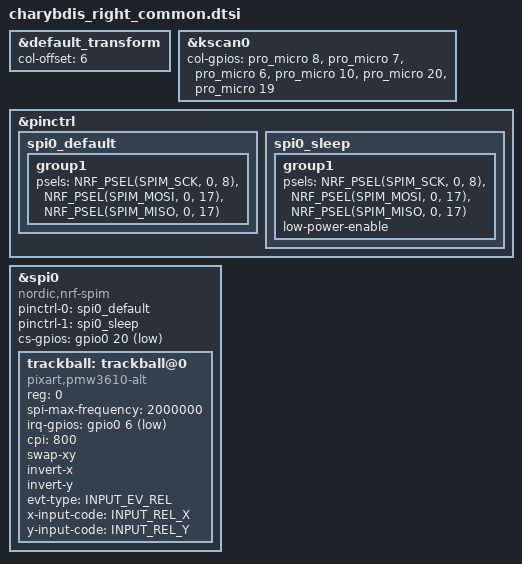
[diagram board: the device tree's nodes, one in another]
/*
 * Copyright (c) 2024 The ZMK Contributors
 * SPDX-License-Identifier: MIT
 *
 * Common hardware configuration for Charybdis right keyboard variants
 * Shared between charybdis_right_standalone and dongle_charybdis_right
 */

#include "charybdis.dtsi"
#include <zephyr/dt-bindings/input/input-event-codes.h>

&default_transform {
	col-offset = <6>;
};

&kscan0 {
	col-gpios
		= <&pro_micro 8 (GPIO_ACTIVE_HIGH | GPIO_PULL_DOWN)>
		, <&pro_micro 7 (GPIO_ACTIVE_HIGH | GPIO_PULL_DOWN)>
		, <&pro_micro 6 (GPIO_ACTIVE_HIGH | GPIO_PULL_DOWN)>
		, <&pro_micro 10 (GPIO_ACTIVE_HIGH | GPIO_PULL_DOWN)>
		, <&pro_micro 20 (GPIO_ACTIVE_HIGH | GPIO_PULL_DOWN)>
		, <&pro_micro 19 (GPIO_ACTIVE_HIGH | GPIO_PULL_DOWN)>
  ;
};

&pinctrl {
    spi0_default: spi0_default {
        group1 {
            psels = <NRF_PSEL(SPIM_SCK, 0, 8)>,
                <NRF_PSEL(SPIM_MOSI, 0, 17)>,
                <NRF_PSEL(SPIM_MISO, 0, 17)>;
        };
    };

    spi0_sleep: spi0_sleep {
        group1 {
            psels = <NRF_PSEL(SPIM_SCK, 0, 8)>,
                <NRF_PSEL(SPIM_MOSI, 0, 17)>,
                <NRF_PSEL(SPIM_MISO, 0, 17)>;
            low-power-enable;
        };
    };

};

&spi0 {
    status = "okay";
    compatible = "nordic,nrf-spim";
    pinctrl-0 = <&spi0_default>;
    pinctrl-1 = <&spi0_sleep>;
    pinctrl-names = "default", "sleep";
    cs-gpios = <&gpio0 20 GPIO_ACTIVE_LOW>;

    trackball: trackball@0 {
        status = "okay";
        compatible = "pixart,pmw3610-alt";
        reg = <0>;
        spi-max-frequency = <2000000>;
        irq-gpios = <&gpio0 6 (GPIO_ACTIVE_LOW | GPIO_PULL_UP)>;
        cpi = <800>;
        swap-xy;
        invert-x;
        invert-y;
        evt-type = <INPUT_EV_REL>;
        x-input-code = <INPUT_REL_X>;
        y-input-code = <INPUT_REL_Y>;
        /* force-awake intentionally NOT set: in zmk-pmw3610-driver (zmk-0.4) the
           activity-state listener that is supposed to release force-awake on IDLE
           matches compatible "pixart,pmw3610" while the device is "pixart,pmw3610-alt",
           so it never runs and the sensor stays in full-rate mode forever, streaming
           jitter/dust motion over split 24/7. Normal downshift is used instead. */
    };
};
